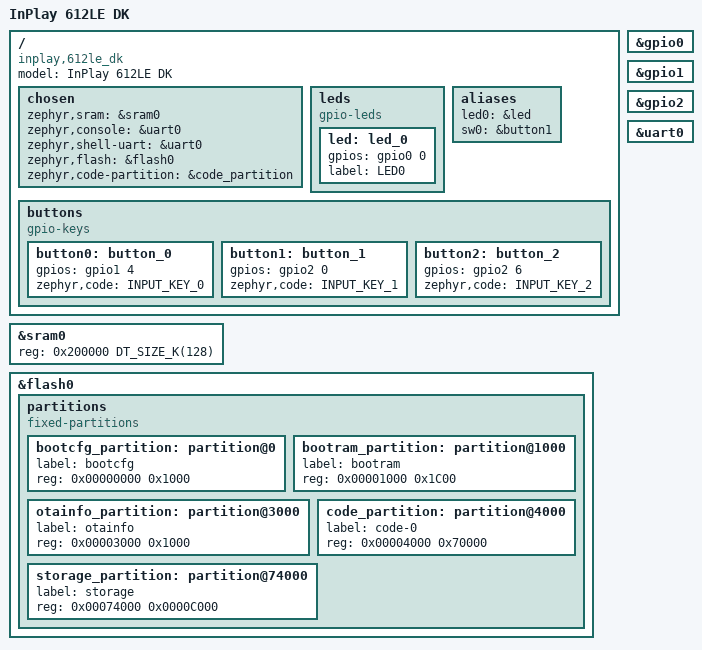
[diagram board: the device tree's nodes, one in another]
/dts-v1/;
#include <inplay/in612le.dtsi>
#include <mem.h>
#include "inplaydk_in612le-pinctrl.dtsi"
#include <zephyr/dt-bindings/input/input-event-codes.h>

/ {
	model = "InPlay 612LE DK";
	compatible = "inplay,612le_dk";
	chosen {
		zephyr,sram = &sram0;
        zephyr,console = &uart0;
		zephyr,shell-uart = &uart0;
		zephyr,flash = &flash0;
		zephyr,code-partition = &code_partition;
	};
	leds {
		compatible = "gpio-leds";
		led: led_0 {
			gpios = <&gpio0 0 GPIO_ACTIVE_HIGH>;
			label = "LED0";
		};
	};

	aliases {
		led0 = &led;
	};

	buttons {
		compatible = "gpio-keys";
		button0: button_0 {
			gpios = <&gpio1 4 GPIO_PULL_UP>;
			zephyr,code = <INPUT_KEY_0>;
		};
		button1: button_1 {
			gpios = <&gpio2 0 GPIO_PULL_UP>;
			zephyr,code = <INPUT_KEY_1>;
		};
		button2: button_2 {
			gpios = <&gpio2 6 GPIO_PULL_UP>;
			zephyr,code = <INPUT_KEY_2>;
		};
	};

	aliases {
		sw0 = &button1;
     };
};
&gpio0 {
	status = "okay";
};
&gpio1 {
	status = "okay";
};
&gpio2 {
	status = "okay";
};
&uart0 {
    status = "okay";
};
&sram0 {
	reg = <0x200000 DT_SIZE_K(128)>;
};

&flash0 {

	partitions {
		compatible = "fixed-partitions";
		#address-cells = <1>;
		#size-cells = <1>;
		bootcfg_partition: partition@0 {
			label = "bootcfg";
			reg = <0x00000000 0x1000>;
		};
		bootram_partition: partition@1000 {
			label = "bootram";
			reg = <0x00001000 0x1C00>;
		};
		otainfo_partition: partition@3000 {
			label = "otainfo";
			reg = <0x00003000 0x1000>;
		};
		code_partition: partition@4000 {
			label = "code-0";
			reg = <0x00004000 0x70000>;
		};
		storage_partition: partition@74000 {
			label = "storage";
			reg = <0x00074000 0x0000C000>;
		};
	};
};
